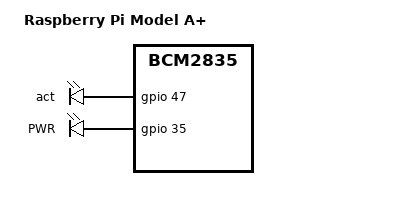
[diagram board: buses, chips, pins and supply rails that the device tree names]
/dts-v1/;
#include "bcm2835.dtsi"
#include "bcm2835-rpi.dtsi"

/ {
	compatible = "raspberrypi,model-a-plus", "brcm,bcm2835";
	model = "Raspberry Pi Model A+";

	leds {
		act {
			gpios = <&gpio 47 0>;
		};

		pwr {
			label = "PWR";
			gpios = <&gpio 35 0>;
			default-state = "keep";
			linux,default-trigger = "default-on";
		};
	};
};

&gpio {
	pinctrl-0 = <&i2c0_gpio0
		     &i2c1_gpio2
		     &gpclk0_gpio4
		     &gpclk1_gpio5
		     &spi0_gpio7
		     &pcm_gpio18
		     &pwm0_gpio40
		     &pwm1_gpio45
		     &gpioout
		     &alt3>;
};
